VERSION ""

NS_ :

BS_:

BU_: XXX

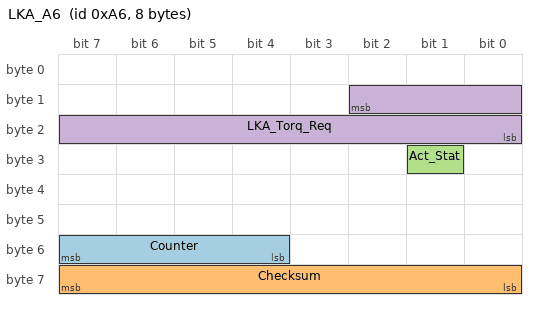
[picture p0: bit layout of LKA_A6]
BO_ 166 LKA_A6: 8 XXX
 SG_ Counter : 55|4@0+ (1,0) [0|15] "" XXX
 SG_ Checksum : 63|8@0+ (1,0) [0|255] "" XXX
 SG_ Act_Stat : 25|1@0+ (1,0) [0|1] "" XXX
 SG_ LKA_Torq_Req : 10|11@0+ (1,-1024) [0|7] "" XXX

BO_ 163 NEW_MSG_1: 8 XXX
 SG_ NEW_SIGNAL_1 : 30|7@0+ (1,0) [0|127] "" XXX

BO_ 127 NEW_MSG_2: 8 XXX

BO_ 121 Dyna: 8 XXX
 SG_ VS : 39|16@0+ (1,0) [0|255] "" XXX
